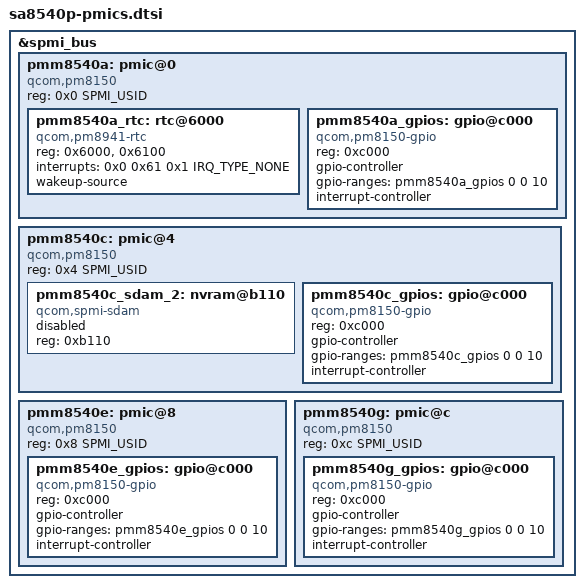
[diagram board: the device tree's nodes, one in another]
// SPDX-License-Identifier: BSD-3-Clause
/*
 * Copyright (c) 2021, The Linux Foundation. All rights reserved.
 * Copyright (c) 2022, Linaro Limited
 */

#include <dt-bindings/interrupt-controller/irq.h>
#include <dt-bindings/spmi/spmi.h>

&spmi_bus {
	pmm8540a: pmic@0 {
		compatible = "qcom,pm8150", "qcom,spmi-pmic";
		reg = <0x0 SPMI_USID>;
		#address-cells = <1>;
		#size-cells = <0>;

		pmm8540a_rtc: rtc@6000 {
			compatible = "qcom,pm8941-rtc";
			reg = <0x6000>, <0x6100>;
			reg-names = "rtc", "alarm";
			interrupts = <0x0 0x61 0x1 IRQ_TYPE_NONE>;
			wakeup-source;
		};

		pmm8540a_gpios: gpio@c000 {
			compatible = "qcom,pm8150-gpio", "qcom,spmi-gpio";
			reg = <0xc000>;
			gpio-controller;
			gpio-ranges = <&pmm8540a_gpios 0 0 10>;
			#gpio-cells = <2>;
			interrupt-controller;
			#interrupt-cells = <2>;
		};
	};

	pmm8540c: pmic@4 {
		compatible = "qcom,pm8150", "qcom,spmi-pmic";
		reg = <0x4 SPMI_USID>;
		#address-cells = <1>;
		#size-cells = <0>;

		pmm8540c_sdam_2: nvram@b110 {
			compatible = "qcom,spmi-sdam";
			reg = <0xb110>;
			#address-cells = <1>;
			#size-cells = <1>;
			ranges = <0 0xb110 0xb0>;
			status = "disabled";
		};

		pmm8540c_gpios: gpio@c000 {
			compatible = "qcom,pm8150-gpio", "qcom,spmi-gpio";
			reg = <0xc000>;
			gpio-controller;
			gpio-ranges = <&pmm8540c_gpios 0 0 10>;
			#gpio-cells = <2>;
			interrupt-controller;
			#interrupt-cells = <2>;
		};
	};

	pmm8540e: pmic@8 {
		compatible = "qcom,pm8150", "qcom,spmi-pmic";
		reg = <0x8 SPMI_USID>;
		#address-cells = <1>;
		#size-cells = <0>;

		pmm8540e_gpios: gpio@c000 {
			compatible = "qcom,pm8150-gpio", "qcom,spmi-gpio";
			reg = <0xc000>;
			gpio-controller;
			gpio-ranges = <&pmm8540e_gpios 0 0 10>;
			#gpio-cells = <2>;
			interrupt-controller;
			#interrupt-cells = <2>;
		};
	};

	pmm8540g: pmic@c {
		compatible = "qcom,pm8150", "qcom,spmi-pmic";
		reg = <0xc SPMI_USID>;
		#address-cells = <1>;
		#size-cells = <0>;

		pmm8540g_gpios: gpio@c000 {
			compatible = "qcom,pm8150-gpio", "qcom,spmi-gpio";
			reg = <0xc000>;
			gpio-controller;
			gpio-ranges = <&pmm8540g_gpios 0 0 10>;
			#gpio-cells = <2>;
			interrupt-controller;
			#interrupt-cells = <2>;
		};
	};
};
